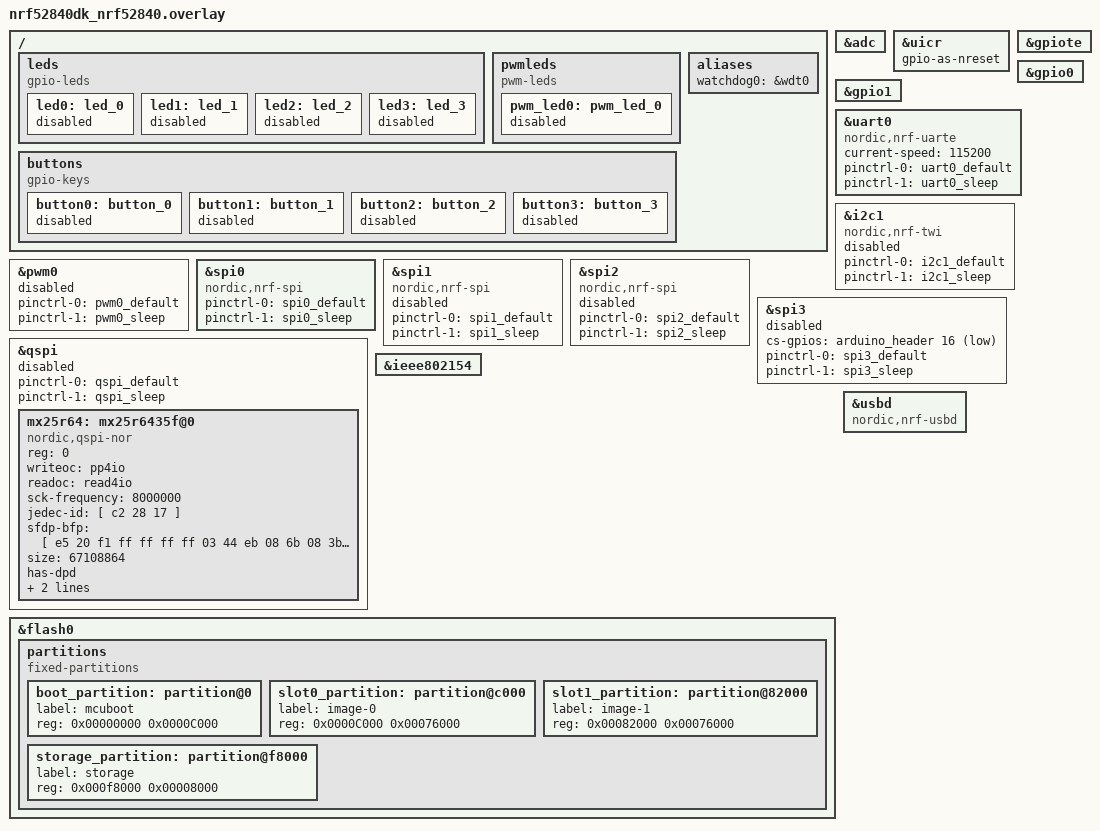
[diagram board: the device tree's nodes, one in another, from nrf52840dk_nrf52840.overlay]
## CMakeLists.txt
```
# SPDX-License-Identifier: LicenseRef-Nordic-5-Clause

cmake_minimum_required(VERSION 3.13.1)
find_package(Zephyr REQUIRED HINTS $ENV{ZEPHYR_BASE})
project(target)


# set(dfu_common_dir ${ZEPHYR_NRF_MODULE_DIR}/samples/bluetooth/mesh/dfu/common/src)

# include_directories(${dfu_common_dir})

target_include_directories(app PRIVATE include)
target_sources(app PRIVATE src/main.c src/lkp1/framing.c
  src/lkp1/certificate.c src/lkp1/crypto.c src/lkp1/keys.c
  src/lkp1/crypto_psa.c src/lkp1/server.c)
target_sources(app PRIVATE src/lkp1/acl.c)
```

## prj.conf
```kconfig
# LKP1 lock, nRF52840 DK, NCS 3.4.0. Internal flash only.
CONFIG_MAIN_STACK_SIZE=4096
CONFIG_SYSTEM_WORKQUEUE_STACK_SIZE=4096
CONFIG_HEAP_MEM_POOL_SIZE=2048

# BLE NUS. Link pairing is Just Works; identity is checked by LKP1.
CONFIG_BT=y
CONFIG_BT_PERIPHERAL=y
CONFIG_BT_NUS=y
CONFIG_BT_SMP=y
CONFIG_BT_SMP_ENFORCE_MITM=n
CONFIG_BT_SMP_SC_ONLY=y
CONFIG_BT_BONDABLE=n
CONFIG_BT_MAX_CONN=1
CONFIG_BT_DEVICE_NAME="LKP1-Lock"
CONFIG_BT_L2CAP_TX_MTU=247
CONFIG_BT_BUF_ACL_RX_SIZE=251
CONFIG_BT_BUF_ACL_TX_SIZE=251
CONFIG_BT_CTLR_DATA_LENGTH_MAX=251

# Crypto operations use PSA; no locally implemented primitives.
CONFIG_PSA_CRYPTO=y
CONFIG_PSA_WANT_ALG_SHA_256=y
CONFIG_PSA_WANT_ALG_HMAC=y
CONFIG_PSA_WANT_KEY_TYPE_HMAC=y
CONFIG_PSA_WANT_ALG_HKDF_EXPAND=y
CONFIG_PSA_WANT_ALG_ECDSA=y
CONFIG_PSA_WANT_ECC_SECP_R1_256=y
CONFIG_PSA_WANT_ECC_MONTGOMERY_255=y
CONFIG_PSA_WANT_ALG_GCM=y
CONFIG_PSA_WANT_KEY_TYPE_AES=y
CONFIG_PSA_WANT_AES_KEY_SIZE_128=y

# Signed MCUboot image and BLE SMP upload, using the two internal flash slots.
CONFIG_BOOTLOADER_MCUBOOT=y
CONFIG_FLASH=y
CONFIG_FLASH_MAP=y
CONFIG_STREAM_FLASH=y
CONFIG_IMG_MANAGER=y
CONFIG_MCUMGR=y
CONFIG_ZCBOR=y
CONFIG_CRC=y
CONFIG_MCUMGR_GRP_IMG=y
CONFIG_MCUMGR_GRP_OS=y
CONFIG_MCUMGR_TRANSPORT_BT=y
CONFIG_MCUMGR_TRANSPORT_BT_PERM_RW_ENCRYPT=y
CONFIG_MCUMGR_TRANSPORT_BT_REASSEMBLY=y
CONFIG_MCUMGR_TRANSPORT_NETBUF_SIZE=1024

# Keep production logs free of protocol secrets.
CONFIG_LOG=y
CONFIG_LOG_MAX_LEVEL=2
```

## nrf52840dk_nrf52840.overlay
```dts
// To get started, press Ctrl+Space to bring up the completion menu and view the available nodes.

// You can also use the buttons in the sidebar to perform actions on nodes.
// Actions currently available include:

// * Enabling / disabling the node
// * Adding the bus to a bus
// * Removing the node
// * Connecting ADC channels

// For more help, browse the DeviceTree documentation at https: //docs.zephyrproject.org/latest/guides/dts/index.html
// You can also visit the nRF DeviceTree extension documentation at https: //docs.nordicsemi.com/bundle/nrf-connect-vscode/page/guides/ncs_configure_app.html#devicetree-support-in-the-extension
/*
 * Copyright (c) 2017 Linaro Limited
 *
 * SPDX-License-Identifier: Apache-2.0
 */
/ {


    leds {
        compatible = "gpio-leds";
        led0: led_0 {
            status = "disabled";
        };
        led1: led_1 {
            status = "disabled";
        };
        led2: led_2 {
            status = "disabled";
        };
        led3: led_3 {
            status = "disabled";
        };
    };
    
    pwmleds {
        compatible = "pwm-leds";
        pwm_led0: pwm_led_0 {
            status = "disabled";
        };
    };


    buttons {
        compatible = "gpio-keys";
        button0: button_0 {
            status = "disabled";
        };
        button1: button_1 {
            status = "disabled";
        };
        button2: button_2 {
            status = "disabled";
        };
        button3: button_3 {
            status = "disabled";
        };
    };




    /* These aliases are provided for compatibility with samples */
    aliases {
        watchdog0 = &wdt0;

    };
};

&adc {
    status = "okay";
};

&uicr {
    gpio-as-nreset;
};

&gpiote {
    status = "okay";
};

&gpio0 {
    status = "okay";
};

&gpio1 {
    status = "okay";
};

&uart0 {
    compatible = "nordic,nrf-uarte";
    status = "okay";
    current-speed = <115200>;
    pinctrl-0 = <&uart0_default>;
    pinctrl-1 = <&uart0_sleep>;
    pinctrl-names = "default", "sleep";
};





&i2c1 {
    compatible = "nordic,nrf-twi";
    /* Cannot be used together with spi1. */
    status = "disabled";
    pinctrl-0 = <&i2c1_default>;
    pinctrl-1 = <&i2c1_sleep>;
    pinctrl-names = "default", "sleep";
};

&pwm0 {
    status = "disabled";
    pinctrl-0 = <&pwm0_default>;
    pinctrl-1 = <&pwm0_sleep>;
    pinctrl-names = "default", "sleep";
};

&spi0 {
    compatible = "nordic,nrf-spi";
    /* Cannot be used together with i2c0. */
    /* status = "okay"; */
    pinctrl-0 = <&spi0_default>;
    pinctrl-1 = <&spi0_sleep>;
    pinctrl-names = "default", "sleep";
};

&spi1 {
    compatible = "nordic,nrf-spi";
    status = "disabled";
    pinctrl-0 = <&spi1_default>;
    pinctrl-1 = <&spi1_sleep>;
    pinctrl-names = "default", "sleep";
};

&spi2 {
    compatible = "nordic,nrf-spi";
    status = "disabled";
    pinctrl-0 = <&spi2_default>;
    pinctrl-1 = <&spi2_sleep>;
    pinctrl-names = "default", "sleep";
};

&qspi {
    status = "disabled";
    pinctrl-0 = <&qspi_default>;
    pinctrl-1 = <&qspi_sleep>;
    pinctrl-names = "default", "sleep";
    mx25r64: mx25r6435f@0 {
        compatible = "nordic,qspi-nor";
        reg = <0>;
        /* MX25R64 supports only pp and pp4io */
        writeoc = "pp4io";
        /* MX25R64 supports all readoc options */
        readoc = "read4io";
        sck-frequency = <8000000>;
        jedec-id = [ c2 28 17  ];
        sfdp-bfp = [ e5 20 f1 ff ff ff ff 03 44 eb 08 6b 08 3b 04 bb ee ff ff ff ff ff 00 ff ff ff 00 ff 0c 20 0f 52 10 d8 00 ff 23 72 f5 00 82 ed 04 cc 44 83 68 44 30 b0 30 b0 f7 c4 d5 5c 00 be 29 ff f0 d0 ff ff  ];
        size = <67108864>;
        has-dpd;
        t-enter-dpd = <10000>;
        t-exit-dpd = <35000>;
    };
};

arduino_spi: &spi3 {
    status = "disabled";
    cs-gpios = <&arduino_header 16 GPIO_ACTIVE_LOW>; /* D10 */
    pinctrl-0 = <&spi3_default>;
    pinctrl-1 = <&spi3_sleep>;
    pinctrl-names = "default", "sleep";
};

&ieee802154 {
    status = "okay";
};

&flash0 {

    partitions {
        compatible = "fixed-partitions";
        #address-cells = <1>;
        #size-cells = <1>;

        boot_partition: partition@0 {
            label = "mcuboot";
            reg = <0x00000000 0x0000C000>;
        };
        slot0_partition: partition@c000 {
            label = "image-0";
            reg = <0x0000C000 0x00076000>;
        };
        slot1_partition: partition@82000 {
            label = "image-1";
            reg = <0x00082000 0x00076000>;
        };

        /*
         * The flash starting at 0x000f8000 and ending at
         * 0x000fffff is reserved for use by the application.
         */

        /*
         * Storage partition will be used by FCB/LittleFS/NVS
         * if enabled.
         */
        storage_partition: partition@f8000 {
            label = "storage";
            reg = <0x000f8000 0x00008000>;
        };
    };
};

zephyr_udc0: &usbd {
    compatible = "nordic,nrf-usbd";
    status = "okay";
};
```

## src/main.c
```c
/* BLE/NUS adapter. All protocol decisions belong to lkp1/server.c. */
#include <zephyr/kernel.h>
#include <zephyr/bluetooth/bluetooth.h>
#include <zephyr/bluetooth/conn.h>
#include <zephyr/sys/util.h>
#include <bluetooth/services/nus.h>
#include <psa/crypto.h>
#include <zephyr/dfu/mcuboot.h>
#include <string.h>
#include "lkp1/framing.h"
#include "lkp1/server.h"
#include "lkp1/crypto_psa.h"
#include "lkp1/acl.h"

/* A generated prototype credential header is optional at compile time. When
 * absent, this firmware advertises but rejects every LKP1 handshake. */
#if __has_include("factory_credentials.h")
#include "factory_credentials.h"
#endif

static struct bt_conn *active_conn;
static bool link_ready;
static bool closing;
static int64_t closing_started_ms;
static unsigned int notifications_pending;
static struct lkp1_decoder decoder;
static struct lkp1_server server;
static uint8_t tx_buffer[1028];
static size_t tx_size, tx_offset;
#if defined(LKP1_FACTORY_PROVISIONED)
static uint8_t f2a[73], f2b[458];
#endif
static uint8_t app_plain[LKP1_MAX_APP_PLAINTEXT];
static unsigned int failures;
static int64_t backoff_until_ms;

static void disconnect_with_alert(uint8_t code)
{
    if (active_conn != NULL) {
        uint8_t alert[5] = { 1, LKP1_RECORD_ALERT, 0, 1, code };
        closing = true;
        closing_started_ms = k_uptime_get();
        if (!link_ready || bt_nus_send(active_conn, alert,
                                        sizeof(alert)) != 0) {
            (void)bt_conn_disconnect(active_conn,
                                     BT_HCI_ERR_REMOTE_USER_TERM_CONN);
        } else {
            notifications_pending++;
        }
    }
}

static void failed(uint8_t code)
{
    lkp1_server_reset(&server);
    lkp1_decoder_reset(&decoder);
    tx_size = tx_offset = 0;
    failures++;
    if (failures >= 3) {
        unsigned int shift = MIN(failures - 3, 6u);
        int64_t delay = MIN(1u << shift, 60u);
        backoff_until_ms = k_uptime_get() + delay * 1000;
    }
    disconnect_with_alert(code);
}

static void send_next(void)
{
    if (active_conn == NULL || !link_ready || closing ||
        tx_offset == tx_size) {
        return;
    }
    uint16_t mtu = bt_gatt_get_mtu(active_conn);
    size_t limit = mtu > 3 ? mtu - 3 : 0;
    size_t remaining = tx_size - tx_offset;
    size_t count = MIN(remaining, limit);
    if (count == 0 || bt_nus_send(active_conn, tx_buffer + tx_offset,
                                   count) != 0) {
        failed(1);
        return;
    }
    tx_offset += count;
    notifications_pending++;
}

static void sent(struct bt_conn *conn)
{
    if (conn == active_conn) {
        if (notifications_pending != 0) {
            notifications_pending--;
        }
        if (closing) {
            if (notifications_pending == 0) {
                (void)bt_conn_disconnect(conn,
                                         BT_HCI_ERR_REMOTE_USER_TERM_CONN);
            }
        } else {
            send_next();
        }
    }
}

static int on_record(void *context, uint8_t type, const uint8_t *body,
                     uint16_t body_len)
{
    ARG_UNUSED(context);
#if defined(LKP1_FACTORY_PROVISIONED)
    if (type == LKP1_RECORD_HANDSHAKE && server.state == LKP1_IDLE) {
        size_t a_len = 0, b_len = 0;
        if (tx_size != tx_offset || lkp1_server_f1(&server,
            &lkp1_factory_identity, &lkp1_psa_crypto, body, body_len,
            k_uptime_get(), f2a, &a_len, f2b, &b_len) != 0) {
            return -1;
        }
        memcpy(tx_buffer, f2a, a_len);
        memcpy(tx_buffer + a_len, f2b, b_len);
        tx_size = a_len + b_len;
        tx_offset = 0;
        send_next();
        return 0;
    }
    if (type == LKP1_RECORD_HANDSHAKE_ENC &&
        server.state == LKP1_WAIT_F3) {
        if (tx_size != tx_offset ||
            lkp1_server_f3(&server, &lkp1_factory_identity,
            &lkp1_psa_crypto, body, body_len, k_uptime_get()) != 0) {
            return LKP1_ERR_AUTH;
        }
        failures = 0;
        return 0;
    }
    if (type == LKP1_RECORD_APP_DATA && server.state == LKP1_OPEN) {
        size_t plain_len = 0;
        if (lkp1_server_open_data(&server, &lkp1_psa_crypto, body,
            body_len, k_uptime_get(), app_plain, &plain_len) != 0) {
            return LKP1_ERR_AUTH;
        }
        if (!lkp1_acl_contains(server.client_id,
            lkp1_factory_allowed_ids, lkp1_factory_allowed_count)) {
            lkp1_secure_zero(app_plain, plain_len);
            return LKP1_ERR_AUTH;
        }
        /* Command 1 is a read-only demo status. No unlock actuator is wired
         * into this transport. Unknown commands are protocol errors. */
        if (plain_len == 0 || app_plain[0] != 1 || tx_size != tx_offset) {
            lkp1_secure_zero(app_plain, plain_len);
            return -1;
        }
        static const uint8_t response[] = { 0x81, 'r', 'e', 'a', 'd', 'y' };
        if (lkp1_server_seal_data(&server, &lkp1_psa_crypto, response,
            sizeof(response), k_uptime_get(), tx_buffer, &tx_size) != 0) {
            lkp1_secure_zero(app_plain, plain_len);
            return -1;
        }
        tx_offset = 0;
        send_next();
        lkp1_secure_zero(app_plain, plain_len);
        return 0;
    }
#else
    ARG_UNUSED(type);
    ARG_UNUSED(body);
    ARG_UNUSED(body_len);
#endif
    return -1;
}

static void receive(struct bt_conn *conn, const uint8_t *data, uint16_t len)
{
    if (conn != active_conn || closing || data == NULL || len == 0) {
        return;
    }
    if (!link_ready) {
        failed(1);
        return;
    }
    int rc = lkp1_decoder_feed(&decoder, data, len, k_uptime_get(),
                                on_record, NULL);
    if (rc != 0) {
        failed(rc == LKP1_ERR_AUTH ? 2 : 1);
    }
}

static struct bt_nus_cb nus_callbacks = {
    .received = receive,
    .sent = sent,
};

static void connected(struct bt_conn *conn, uint8_t err)
{
    if (err != 0 || conn == NULL) {
        return;
    }
    if (active_conn != NULL || k_uptime_get() < backoff_until_ms) {
        (void)bt_conn_disconnect(conn, BT_HCI_ERR_REMOTE_USER_TERM_CONN);
        return;
    }
    active_conn = bt_conn_ref(conn);
    link_ready = bt_conn_get_security(conn) >= BT_SECURITY_L2;
    closing = false;
    notifications_pending = 0;
    lkp1_decoder_reset(&decoder);
    lkp1_server_reset(&server);
    tx_size = tx_offset = 0;
    /* Just Works is only transport encryption; LKP1 authenticates peers. */
    if (!link_ready && bt_conn_set_security(conn, BT_SECURITY_L2) != 0) {
        (void)bt_conn_disconnect(conn, BT_HCI_ERR_REMOTE_USER_TERM_CONN);
    }
}

static void security_changed(struct bt_conn *conn, bt_security_t level,
                             enum bt_security_err err)
{
    if (conn != active_conn) {
        return;
    }
    link_ready = err == BT_SECURITY_ERR_SUCCESS && level >= BT_SECURITY_L2;
    if (!link_ready) {
        (void)bt_conn_disconnect(conn, BT_HCI_ERR_REMOTE_USER_TERM_CONN);
    }
}

static void disconnected(struct bt_conn *conn, uint8_t reason)
{
    ARG_UNUSED(reason);
    if (conn == active_conn) {
        lkp1_decoder_reset(&decoder);
        lkp1_server_reset(&server);
        lkp1_secure_zero(tx_buffer, sizeof(tx_buffer));
        lkp1_secure_zero(app_plain, sizeof(app_plain));
        tx_size = tx_offset = 0;
        link_ready = false;
        closing = false;
        notifications_pending = 0;
        bt_conn_unref(active_conn);
        active_conn = NULL;
    }
}

static struct bt_conn_cb conn_callbacks = {
    .connected = connected,
    .disconnected = disconnected,
    .security_changed = security_changed,
};

static void timeout_check(struct k_work *work);
K_WORK_DELAYABLE_DEFINE(timeout_work, timeout_check);

static void timeout_check(struct k_work *work)
{
    ARG_UNUSED(work);
    int64_t now = k_uptime_get();
    if (active_conn != NULL && closing &&
        now - closing_started_ms > 1000) {
        (void)bt_conn_disconnect(active_conn,
                                 BT_HCI_ERR_REMOTE_USER_TERM_CONN);
    } else if (active_conn != NULL && !closing &&
        ((decoder.header_received != 0 &&
          now - decoder.last_fragment_ms > LKP1_FRAGMENT_TIMEOUT_MS) ||
         (server.state == LKP1_WAIT_F3 &&
          now - server.started_ms > 10000) ||
         (server.state == LKP1_OPEN &&
          now - server.opened_ms > 24LL * 60 * 60 * 1000))) {
        failed(1);
    }
    (void)k_work_reschedule(&timeout_work, K_SECONDS(1));
}

int main(void)
{
    static const uint8_t flags = BT_LE_AD_GENERAL | BT_LE_AD_NO_BREDR;
    static const uint8_t nus_uuid[] = { BT_UUID_NUS_VAL };
    static const struct bt_data advertising[] = {
        BT_DATA(BT_DATA_FLAGS, &flags, sizeof(flags)),
        BT_DATA(BT_DATA_NAME_COMPLETE, CONFIG_BT_DEVICE_NAME,
                sizeof(CONFIG_BT_DEVICE_NAME) - 1),
    };
    static const struct bt_data scan_response[] = {
        BT_DATA(BT_DATA_UUID128_ALL, nus_uuid, sizeof(nus_uuid)),
    };
    if (psa_crypto_init() != PSA_SUCCESS) {
        return 1;
    }
    lkp1_decoder_reset(&decoder);
    lkp1_server_reset(&server);
    bt_conn_cb_register(&conn_callbacks);
    if (bt_enable(NULL) != 0 || bt_nus_init(&nus_callbacks) != 0) {
        return 1;
    }
    if (bt_le_adv_start(BT_LE_ADV_CONN_FAST_1, advertising,
                        ARRAY_SIZE(advertising), scan_response,
                        ARRAY_SIZE(scan_response)) != 0) {
        return 1;
    }
    /* Confirm an update only after PSA, BLE, NUS and advertising initialized.
     * Product firmware should add device-specific self tests before this. */
    if (!boot_is_img_confirmed() && boot_write_img_confirmed() != 0) {
        return 1;
    }
    (void)k_work_reschedule(&timeout_work, K_SECONDS(1));
    for (;;) {
        k_sleep(K_SECONDS(1));
    }
}
```
